# M2354 register map
File version: 1.0
Registers are 32-bit, read-write, reset 0x0 unless marked. A register's access mark holds for its fields unless they carry their own. Offsets are from the block's base; [hi:lo] are bit positions; {n}, {i} and the like mark numbered series.

## LCD_NS — LCD Register Map
Base 0x500BB000
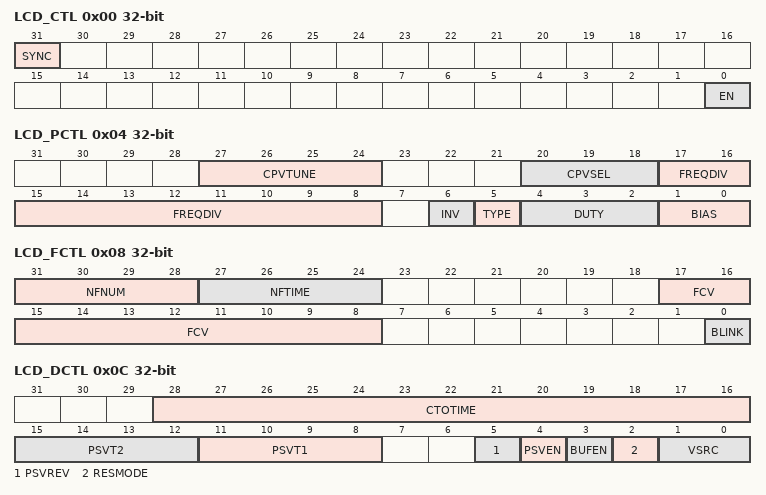
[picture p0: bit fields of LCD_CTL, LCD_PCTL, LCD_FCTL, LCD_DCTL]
0x00 LCD_CTL — LCD Control Register
  [31] SYNC ro — LCD Enable/Disable Synchronizing Indicator (Read Only). When user writes 0/1 to EN (LCD_CTL[0]), the LCD Controller needs some synchronizing time to completely disable/enable the LCD display function. During this time, this bit keeps at 1. Note 1: The synchronizing time to enable LCD display function is not constant. It is between one and two cycles of CLKLCD. Note 2: The LCD display function cannot be disabled until the end of a frame. Thus, the maximum synchronizing time to disable LCD display function could be as long as one frame time.
    0=LCD display function is completely Disabled/Enabled; 1=LCD display function is not yet completely Disabled/Enabled
  [0] EN — LCD Display Enable Bit. Note 1: When user writes 1 to this bit, the LCD Controller needs some synchronizing time to completely enable the LCD display function. Before that, the read value of this bit is still 0. Note 2: When user writes 0 to this bit, the LCD Controller needs some synchronizing time to completely disable the LCD display function. Before that, the read value of this bit is still 1.
    0=LCD display function Disabled; 1=LCD display function Enabled
0x04 LCD_PCTL — LCD Panel Control Register
  [27:24] CPVTUNE — LCD Operating Voltage Fine Tuning. This field is used to fine-tune the LCD operating voltage. Note 1: A unit of voltage is about 0.03 V. Note 2: This field is meaningful only if the VLCD source is the charge pump. Otherwise, this field is ignored.
    0=No tuning; 1=decrease by 1 unit of voltage; {v}=decrease by {v} units of voltage (v=2..7); 8=increase by 8 units of voltage; 9=increase by 7 units of voltage; 10=increase by 6 units of voltage; 11=increase by 5 units of voltage; 12=increase by 4 units of voltage; 13=increase by 3 units of voltage; 14=increase by 2 units of voltage; 15=increase by 1 unit of voltage
  [20:18] CPVSEL — LCD Operating Voltage Select. This field is used to select the LCD operating voltage. Note: This field is meaningful only if the VLCD source is the charge pump. Otherwise, this field is ignored.
    0=2.6 V; 1=2.8 V; 2=3.0 V; 3=3.2 V; 4=3.4 V; 5=3.6 V
  [17:8] FREQDIV — LCD Operating Frequency Divider. The field is used to divide CLKLCD to generate the LCD operating frequency.
  [6] INV — LCD Waveform Inverse. This bit is used to set the inverse LCD waveform.
    0=COM/SEG waveform is normal; 1=COM/SEG waveform is inversed
  [5] TYPE — LCD Waveform Type Selection. This bit is used to select the waveform type.
    0=Type A; 1=Type B
  [4:2] DUTY — LCD Duty Ratio Selection. This field is used to select the duty ratio.
    {v}=1/{v+1} Duty (v=0..7)
  [1:0] BIAS — LCD Bias Level Selection. This field is used to select the bias level.
    1=1/2 Bias; 2=1/3 Bias; 3=1/4 Bias
0x08 LCD_FCTL — LCD Frame Control Register
  [31:28] NFNUM — Number of Frames Inserted By One Null Frame. This field is used to specify the number of continuous normal frames inserted by one null frame. The number of continuous normal frames is (NFNUM + 1) frames.
  [27:24] NFTIME — Null Frame Time. This field is used to configure the length of a null frame. One null frame time is (1 / FLCD) x NFTIME. Note: All COM and SEG output voltages are 0 V during a null frame.
  [17:8] FCV — Frame Counting Value. This field indicates the maximum value that the frame counter can reach. Note 1: The frame counter automatically increases by 1 at the end of every frame. When the counter reaches FCV, it will recounts from 0 at the end of the next frame. At this moment, the hardware sets a dedicated flag to 1, and triggers a dedicated interrupt if it is enabled. Note 2: For type B waveform, the frame counter increases at the end of odd frames, not even frames.
  [0] BLINK — LCD Blinking Enable Bit
    0=LCD blinking function Disabled; 1=LCD blinking function Enabled
0x0C LCD_DCTL — LCD Driving Control Register
  [28:16] CTOTIME — Charging Timer Timeout Time. This field is used to specify the timeout value for the charging timer. When the charging timer reaches this timeout value, a status bit or an interrupt will occur. The timeout is calculated by the following formula:
  [15:12] PSVT2 — Power Saving 'On Time' Setting. The 'On Time' of the power saving mode is calculated as
  [11:8] PSVT1 — Power Saving 'Enable Time' Setting. The 'Enable Time' of the power saving mode is calculated as
  [5] PSVREV — Power Saving Timing Reverse. When the timing is reversed, the original power saving period becomes no power saving, and the original no power saving period becomes power saving.
    0=Timing of power saving is normal; 1=Timing of power saving is reversed
  [4] PSVEN — Power Saving Mode Enable Bit
    0=Power Saving Mode Disabled; 1=Power Saving Mode Enabled
  [3] BUFEN — Voltage Buffer Enable Bit
    0=Voltage Buffer Disabled; 1=Voltage Buffer Enabled
  [2] RESMODE — Resistive Network Driving Mode
    0=Low-Drive Mode; 1=High-Drive Mode
  [1:0] VSRC — LCD Operating Voltage Source. Note: Whenever the LCD controller is disabled, all VLCD sources are automatically cut off.
    0=VLCD Power; 1=AVDD Power; 2=Built-In Charge Pump; 3=None
0x10 LCD_PKGSEL — LCD Package Selection Register
  [0] PKG — Device Package Type Selection
    0=128-Pin Package; 1=64-Pin Package
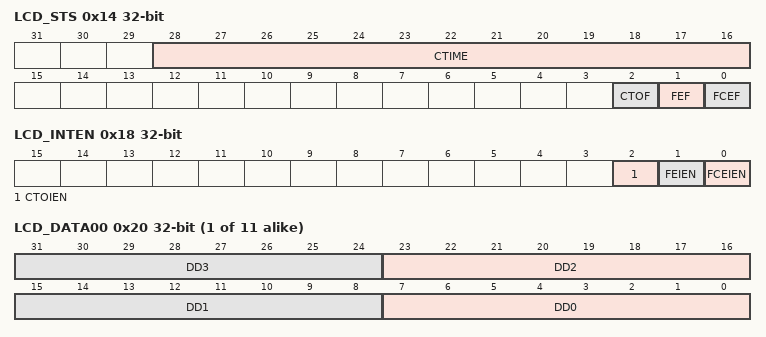
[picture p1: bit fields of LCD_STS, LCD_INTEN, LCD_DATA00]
0x14 LCD_STS — LCD Status Register
  [28:16] CTIME ro — Charging Timer Value (Read Only). The field contains the value of the charging timer. It records the charging time of the charge pump. The charging timer stops counting when the charge pump stops charging or a timeout occurs. At this moment, the hardware dumps the current charging timer value into this field.
  [2] CTOF — Charging Timeout Flag. This flag is automatically set by hardware when the charging timer reaches the timeout value. Note: User can clear this bit by writing 1 to it.
    0=Charging Timeout did not occur; 1=Charging Timeout occurred
  [1] FEF — End of Frame Flag. This flag is automatically set by hardware at the end of a frame. Note 1: User can clear this bit by writing 1 to it. Note 2: For type B waveform, this flag is set only at the end of an odd frame.
    0=End of Frame did not occur; 1=End of Frame occurred
  [0] FCEF — End of Frame Counting Flag. This flag is automatically set by hardware at the end of a frame, and the frame counter value must be equal to FCV (LCD_FCTL[17:8], Frame Counting Value). Note 1: User can clear this bit by writing 1 to it. Note 2: For type B waveform, this flag is set only at the end of an odd frame.
    0=End of Frame Counting did not occur; 1=End of Frame Counting occurred
0x18 LCD_INTEN — LCD Interrupt Enable Register
  [2] CTOIEN — Charging Timeout Interrupt Enable Bit. An interrupt occurs when the charging timer reaches the timeout value.
    0=Charging Timeout Interrupt Disabled; 1=Charging Timeout Interrupt Enabled
  [1] FEIEN — End of Frame Interrupt Enable Bit. An interrupt occurs at the end of a frame. Note: For type B waveform, the interrupt occurs only at the end of an odd frame.
    0=End of Frame Interrupt Disabled; 1=End of Frame Interrupt Enabled
  [0] FCEIEN — End of Frame Counting Interrupt Enable Bit. An interrupt occurs at the end of a frame, and the frame counter value must be equal to FCV (LCD_FCTL[17:8], Frame Counting Value). Note: For type B waveform, the interrupt occurs only at the end of an odd frame.
    0=End of Frame Counting Interrupt Disabled; 1=End of Frame Counting Interrupt Enabled
{0x20+4i} LCD_DATA{i:02} (i=0..10) — LCD Segment Display Data Register {i}
  [all] fields
    0=The pixel is light; 1=The pixel is dark
  [8n+7:8n] DD{n} (n=0..3) — Display Data of Segments S, where S is 4 x N + {n}, and N is 0, 1, 2, ..., 10. Each bit specifies the brightness of each pixel in a segment. LCD_DATA07[{8n+7}:{8n+4}] are ignored, since COMs from 4 to 7 are not used.
